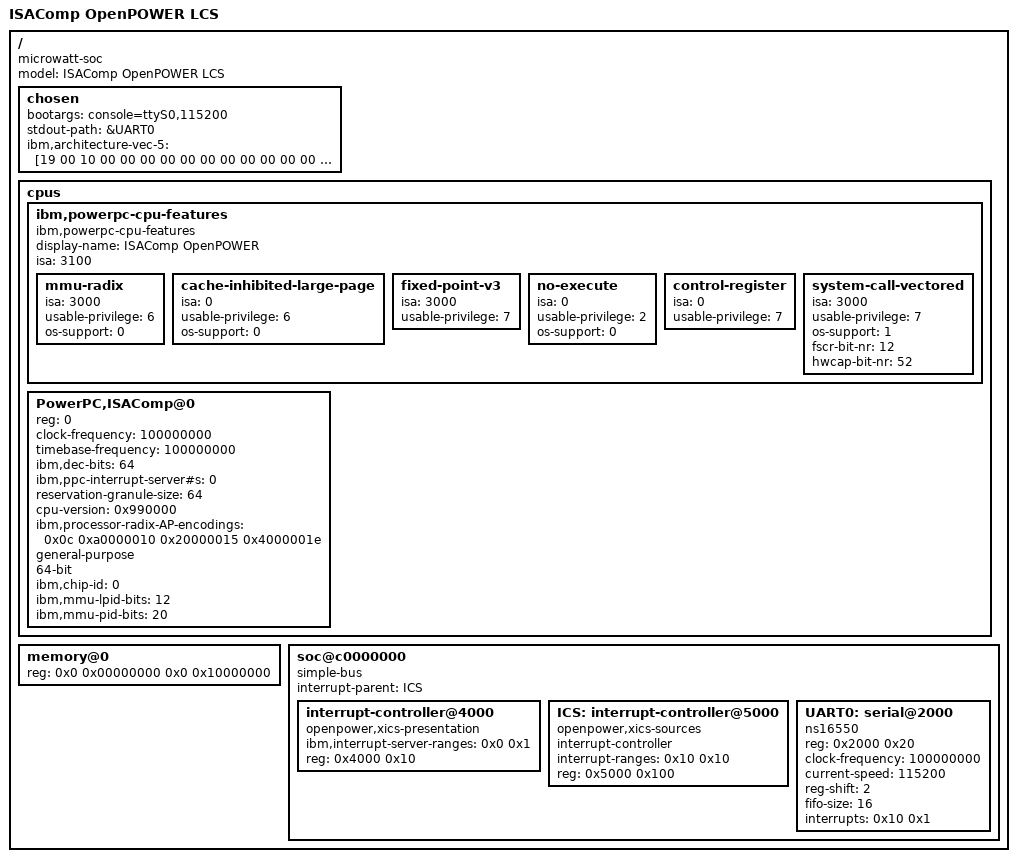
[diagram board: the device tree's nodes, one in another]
// SPDX-License-Identifier: GPL-2.0
// Device tree for OpenPOWER LCS processor generated by ISAComp
// Microwatt-compatible platform
/dts-v1/;

/ {
	compatible = "microwatt-soc";
	model = "ISAComp OpenPOWER LCS";

	#address-cells = <2>;
	#size-cells = <2>;

	chosen {
		bootargs = "console=ttyS0,115200";
		stdout-path = &UART0;
		ibm,architecture-vec-5 = [19 00 10 00 00 00 00 00 00 00 00 00 00 00 00 00
					  00 00 00 00 00 00 00 00 40 00 40];
	};

	cpus {
		#address-cells = <1>;
		#size-cells = <0>;

		ibm,powerpc-cpu-features {
			display-name = "ISAComp OpenPOWER";
			isa = <3100>;
			device_type = "cpu-features";
			compatible = "ibm,powerpc-cpu-features";

			mmu-radix {
				isa = <3000>;
				usable-privilege = <6>;
				os-support = <0>;
			};

			cache-inhibited-large-page {
				isa = <0>;
				usable-privilege = <6>;
				os-support = <0>;
			};

			fixed-point-v3 {
				isa = <3000>;
				usable-privilege = <7>;
			};

			no-execute {
				isa = <0>;
				usable-privilege = <2>;
				os-support = <0>;
			};

			control-register {
				isa = <0>;
				usable-privilege = <7>;
			};

			system-call-vectored {
				isa = <3000>;
				usable-privilege = <7>;
				os-support = <1>;
				fscr-bit-nr = <12>;
				hwcap-bit-nr = <52>;
			};
		};

		PowerPC,ISAComp@0 {
			device_type = "cpu";
			reg = <0>;
			clock-frequency = <100000000>;
			timebase-frequency = <100000000>;
			ibm,dec-bits = <64>;
			ibm,ppc-interrupt-server#s = <0>;
			reservation-granule-size = <64>;
			cpu-version = <0x990000>;
			status = "okay";
			ibm,processor-radix-AP-encodings = <0x0c 0xa0000010 0x20000015 0x4000001e>;
			general-purpose;
			64-bit;
			ibm,chip-id = <0>;
			ibm,mmu-lpid-bits = <12>;
			ibm,mmu-pid-bits = <20>;
		};
	};

	memory@0 {
		device_type = "memory";
		reg = <0x0 0x00000000 0x0 0x10000000>;  // 256MB
	};

	soc@c0000000 {
		compatible = "simple-bus";
		#address-cells = <1>;
		#size-cells = <1>;
		interrupt-parent = <&ICS>;

		ranges = <0 0 0xc0000000 0x40000000>;

		interrupt-controller@4000 {
			compatible = "openpower,xics-presentation", "ibm,ppc-xicp";
			ibm,interrupt-server-ranges = <0x0 0x1>;
			reg = <0x4000 0x10>;
		};

		ICS: interrupt-controller@5000 {
			compatible = "openpower,xics-sources";
			interrupt-controller;
			interrupt-ranges = <0x10 0x10>;
			reg = <0x5000 0x100>;
			#address-cells = <0>;
			#size-cells = <0>;
			#interrupt-cells = <2>;
		};

		UART0: serial@2000 {
			device_type = "serial";
			compatible = "ns16550";
			reg = <0x2000 0x20>;
			clock-frequency = <100000000>;
			current-speed = <115200>;
			reg-shift = <2>;
			fifo-size = <16>;
			interrupts = <0x10 0x1>;
		};
	};
};
